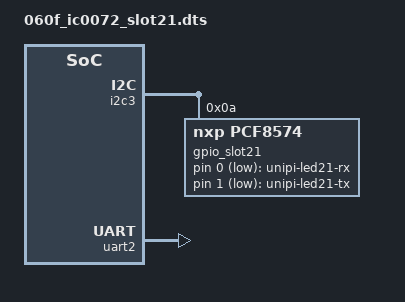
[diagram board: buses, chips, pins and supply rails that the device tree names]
/dts-v1/;


/plugin/;

/ {
	fragment@1 {
		target = <&i2c3>;
		__overlay__ {
			#address-cells = <1>;
			#size-cells = <0>;
			gpio_slot21: pca9501@10 {
				compatible = "nxp,pcf8574";
				gpio-controller;
				#gpio-cells = <2>;
				reg = <10>;
				
			};
		};
	};

	fragment@3 {
		
		target = <&uart2>;
		__overlay__ {
			status = "okay";
		};

	};

	fragment@4 {
		target-path = "/";
		__overlay__ {
			uartleds {
				compatible = "gpio-leds";
				uart-led@0 {
					label = "unipi-led21-rx";
					gpios = <&gpio_slot21 0 1>;
					default-state = "off";
					linux,default-trigger = "ttymxc1-rx";
				};
				uart-led@1 {
					label = "unipi-led21-tx";
					gpios = <&gpio_slot21 1 1>;
					linux,default-trigger = "ttymxc1-tx";
					default-state = "off";
				};
			};
		};
	}; 

};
